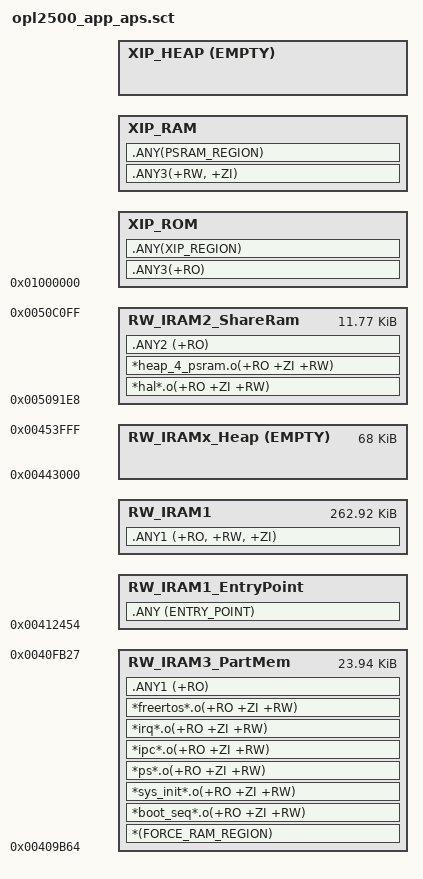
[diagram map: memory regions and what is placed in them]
#! armcc -E

/* User can modify APS_HEAP_START to adjust code size ram and HEAP start address
 * Heap starts equals to program end */
#define APS_HEAP_START      0x443000
#define APS_XIP_SIZE        0x800000        /* Depends on PSRAM size */


/******* Don't modify below *********/
#define APS_PATCH_START     0x412454        /* OPL2500A0 patch start */
#define APS_RAM_START       0x400000
#define APS_RAM_END         0x454000        /* OPL2500 RAM range: 0x400000~0x454000, 336kB */
#define APS_PATCH_LEN       (APS_RAM_END-APS_PATCH_START)
#define APS_HEAP_LENGTH     (APS_RAM_END-APS_HEAP_START)

#define APS_XIP_START           0x01000000      /* Fixed for XIP mapping */
#define APS_XIP_RW_START        0x03000000      /* XIP without cache memory mapping */
#define APS_XIP_END_RWBASE      (APS_XIP_RW_START + APS_XIP_SIZE)

/* Share RAM */
#define SHM_START           0x5091E8
#define SHM_END             0x50C100
#define SHM_LEN             (SHM_END - SHM_START)
/* Rom pbuf memory */
#define APS_PART1_START     0x409B64    /* PBUF memory */
#define APS_PART1_END       0x40FB28
#define APS_PART1_LEN       (APS_PART1_END - APS_PART1_START)

LR_IROM1 APS_PATCH_START APS_PATCH_LEN
{
    RW_IRAM1_EntryPoint +0
    {
        .ANY (ENTRY_POINT)
    }
    RW_IRAM1 +0 APS_PATCH_LEN
    {
        .ANY1 (+RO, +RW, +ZI)
    }
    
    RW_IRAMx_Heap APS_HEAP_START EMPTY APS_HEAP_LENGTH {}
}
ScatterAssert(ImageLimit(LR_IROM1) <= APS_RAM_END)

LR_IROM2 SHM_START SHM_LEN
{
    RW_IRAM2_ShareRam SHM_START SHM_LEN
    {
        *hal*.o(+RO +ZI +RW)
        *heap_4_psram.o(+RO +ZI +RW)
        .ANY2 (+RO)
    }
}
ScatterAssert(ImageLimit(LR_IROM2) <= SHM_END)

LR_IROM3 APS_PART1_START APS_PART1_LEN
{
    RW_IRAM3_PartMem APS_PART1_START APS_PART1_LEN
    {
        *(FORCE_RAM_REGION)
        *boot_seq*.o(+RO +ZI +RW)
        *sys_init*.o(+RO +ZI +RW)
        *ps*.o(+RO +ZI +RW)
        *ipc*.o(+RO +ZI +RW)
        *irq*.o(+RO +ZI +RW)
        *freertos*.o(+RO +ZI +RW)
        /**mw_ota*.o(+RO +ZI +RW)*/
        .ANY1 (+RO)
    }
}
ScatterAssert(ImageLimit(LR_IROM3) <= APS_PART1_END)

LROM_IROM_XIP APS_XIP_START APS_XIP_SIZE
{
    XIP_ROM +0
    {
        .ANY3(+RO)
        .ANY(XIP_REGION)
    }
    XIP_RAM (APS_XIP_RW_START + ImageLength(XIP_ROM))
    {
        .ANY3(+RW, +ZI)
        .ANY(PSRAM_REGION)
    }
    
    XIP_HEAP  AlignExpr(+0,8) EMPTY (APS_XIP_SIZE - (ImageLimit(XIP_RAM) - APS_XIP_RW_START)){}
}
ScatterAssert(ImageLimit(LROM_IROM_XIP) <= APS_XIP_END_RWBASE)
